# Qorvo_SVD register map
Vendor: Qorvo Inc; Series: ARMCM4; File version: 1.0
Registers are 8-bit, read-write, reset 0x0 unless marked. A register's access mark holds for its fields unless they carry their own. Offsets are from the block's base; [hi:lo] are bit positions.

## ADCIF
Base 0x40001040
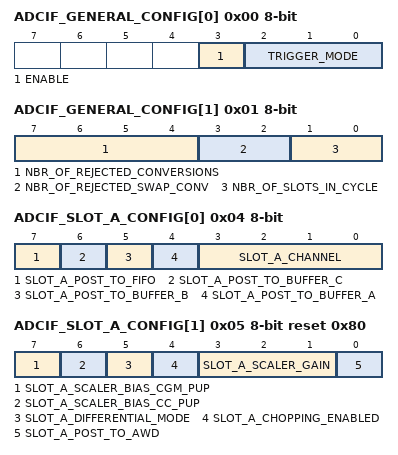
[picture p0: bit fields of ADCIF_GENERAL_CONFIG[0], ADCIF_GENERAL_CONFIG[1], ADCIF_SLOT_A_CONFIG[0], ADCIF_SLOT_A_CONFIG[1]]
0x00 ADCIF_GENERAL_CONFIG[0]
  [3] ENABLE — Enables the adc to perform measurements
  [2:0] TRIGGER_MODE — Defines when the adc measurement is triggered - see enum for possibilities
0x01 ADCIF_GENERAL_CONFIG[1]
  [7:4] NBR_OF_REJECTED_CONVERSIONS — Sets the number of conversions that are rejected between 2 measurements on different channels - acoounts for channel select mux settling time
  [3:2] NBR_OF_REJECTED_SWAP_CONV — Sets the number of conversions that are rejected in a chopped measurement after changing the adc swap input
  [1:0] NBR_OF_SLOTS_IN_CYCLE — Sets the number of slots that are used in a measurement cycle. Up to 4 slots can be used, resulting in an way to measure 4 different channels per cycle. This setting specifies the number of slots-1 (so setting 0 -> 1 slot, setting 3 -> 4 slots)
0x02 ADCIF_GENERAL_CONFIG[2]
  [0] USE_FRACT_CLOCK_AS_SAMPLE_CLK_SOURCE — When set to 1, the clock that is sent to the analog domain is coming from the fractional clock generator (needs bbpll to be on). If not set the clock is a 4MHz 50pct duty cycle clock
0x04 ADCIF_SLOT_A_CONFIG[0]
  [7] SLOT_A_POST_TO_FIFO — post result to result fifo
  [6] SLOT_A_POST_TO_BUFFER_C — post result to third result buffer
  [5] SLOT_A_POST_TO_BUFFER_B — post result to second result buffer
  [4] SLOT_A_POST_TO_BUFFER_A — post result to first result buffer
  [3:0] SLOT_A_CHANNEL — The adc channel for slot a
0x05 ADCIF_SLOT_A_CONFIG[1] reset 0x80
  [7] SLOT_A_SCALER_BIAS_CGM_PUP — constant gm pup
  [6] SLOT_A_SCALER_BIAS_CC_PUP — constant current pup
  [5] SLOT_A_DIFFERENTIAL_MODE — idicates whether we want to do a single_ended or differential measurement
  [4] SLOT_A_CHOPPING_ENABLED — idicates whether we want to do a chopped measurement to cancel out offset errors in the signal path
  [3:1] SLOT_A_SCALER_GAIN — gain to use on the input, note that this is differential gain. Single ended to differential gain will be half of this.
  [0] SLOT_A_POST_TO_AWD — post result to analog watchdog
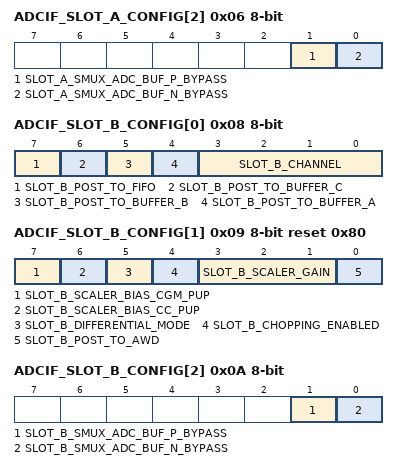
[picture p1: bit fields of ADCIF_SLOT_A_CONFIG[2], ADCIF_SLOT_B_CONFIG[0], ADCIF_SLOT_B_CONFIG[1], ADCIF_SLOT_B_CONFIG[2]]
0x06 ADCIF_SLOT_A_CONFIG[2]
  [1] SLOT_A_SMUX_ADC_BUF_P_BYPASS — bypasses the unity gain buffer (buffer will be forced off) for p-input adc
  [0] SLOT_A_SMUX_ADC_BUF_N_BYPASS — bypasses the unity gain buffer (buffer will be forced off) for n-input adc
0x08 ADCIF_SLOT_B_CONFIG[0]
  [7] SLOT_B_POST_TO_FIFO — post result to result fifo
  [6] SLOT_B_POST_TO_BUFFER_C — post result to third result buffer
  [5] SLOT_B_POST_TO_BUFFER_B — post result to second result buffer
  [4] SLOT_B_POST_TO_BUFFER_A — post result to first result buffer
  [3:0] SLOT_B_CHANNEL — The adc channel for slot b
0x09 ADCIF_SLOT_B_CONFIG[1] reset 0x80
  [7] SLOT_B_SCALER_BIAS_CGM_PUP — constant gm pup
  [6] SLOT_B_SCALER_BIAS_CC_PUP — constant current pup
  [5] SLOT_B_DIFFERENTIAL_MODE — idicates whether we want to do a single_ended or differential measurement
  [4] SLOT_B_CHOPPING_ENABLED — idicates whether we want to do a chopped measurement to cancel out offset errors in the signal path
  [3:1] SLOT_B_SCALER_GAIN — gain to use on the input, note that this is differential gain. Single ended to differential gain will be half of this.
  [0] SLOT_B_POST_TO_AWD — post result to analog watchdog
0x0A ADCIF_SLOT_B_CONFIG[2]
  [1] SLOT_B_SMUX_ADC_BUF_P_BYPASS — bypasses the unity gain buffer (buffer will be forced off) for p-input adc
  [0] SLOT_B_SMUX_ADC_BUF_N_BYPASS — bypasses the unity gain buffer (buffer will be forced off) for n-input adc
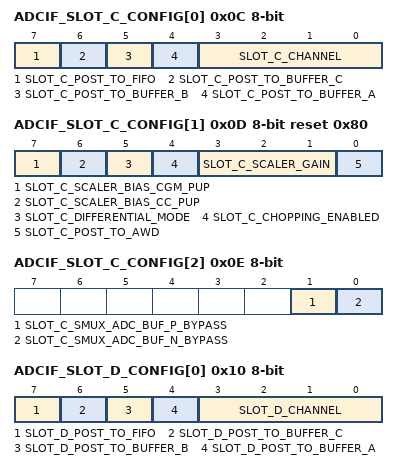
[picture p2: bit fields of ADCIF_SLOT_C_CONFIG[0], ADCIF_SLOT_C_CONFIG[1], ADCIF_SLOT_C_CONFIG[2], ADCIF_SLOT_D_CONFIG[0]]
0x0C ADCIF_SLOT_C_CONFIG[0]
  [7] SLOT_C_POST_TO_FIFO — post result to result fifo
  [6] SLOT_C_POST_TO_BUFFER_C — post result to third result buffer
  [5] SLOT_C_POST_TO_BUFFER_B — post result to second result buffer
  [4] SLOT_C_POST_TO_BUFFER_A — post result to first result buffer
  [3:0] SLOT_C_CHANNEL — The adc channel for slot c
0x0D ADCIF_SLOT_C_CONFIG[1] reset 0x80
  [7] SLOT_C_SCALER_BIAS_CGM_PUP — constant gm pup
  [6] SLOT_C_SCALER_BIAS_CC_PUP — constant current pup
  [5] SLOT_C_DIFFERENTIAL_MODE — idicates whether we want to do a single_ended or differential measurement
  [4] SLOT_C_CHOPPING_ENABLED — idicates whether we want to do a chopped measurement to cancel out offset errors in the signal path
  [3:1] SLOT_C_SCALER_GAIN — gain to use on the input, note that this is differential gain. Single ended to differential gain will be half of this.
  [0] SLOT_C_POST_TO_AWD — post result to analog watchdog
0x0E ADCIF_SLOT_C_CONFIG[2]
  [1] SLOT_C_SMUX_ADC_BUF_P_BYPASS — bypasses the unity gain buffer (buffer will be forced off) for p-input adc
  [0] SLOT_C_SMUX_ADC_BUF_N_BYPASS — bypasses the unity gain buffer (buffer will be forced off) for n-input adc
0x10 ADCIF_SLOT_D_CONFIG[0]
  [7] SLOT_D_POST_TO_FIFO — post result to result fifo
  [6] SLOT_D_POST_TO_BUFFER_C — post result to third result buffer
  [5] SLOT_D_POST_TO_BUFFER_B — post result to second result buffer
  [4] SLOT_D_POST_TO_BUFFER_A — post result to first result buffer
  [3:0] SLOT_D_CHANNEL — The adc channel for slot d
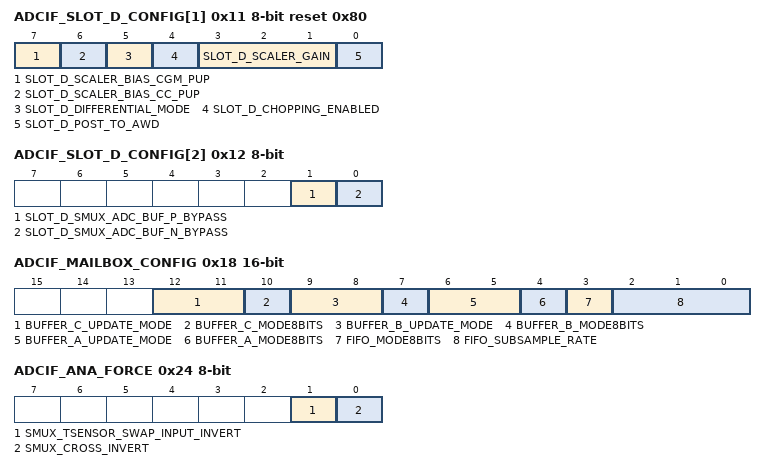
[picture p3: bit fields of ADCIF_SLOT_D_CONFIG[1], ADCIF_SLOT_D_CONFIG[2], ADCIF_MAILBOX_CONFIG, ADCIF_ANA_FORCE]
0x11 ADCIF_SLOT_D_CONFIG[1] reset 0x80
  [7] SLOT_D_SCALER_BIAS_CGM_PUP — constant gm pup
  [6] SLOT_D_SCALER_BIAS_CC_PUP — constant current pup
  [5] SLOT_D_DIFFERENTIAL_MODE — idicates whether we want to do a single_ended or differential measurement
  [4] SLOT_D_CHOPPING_ENABLED — idicates whether we want to do a chopped measurement to cancel out offset errors in the signal path
  [3:1] SLOT_D_SCALER_GAIN — gain to use on the input, note that this is differential gain. Single ended to differential gain will be half of this.
  [0] SLOT_D_POST_TO_AWD — post result to analog watchdog
0x12 ADCIF_SLOT_D_CONFIG[2]
  [1] SLOT_D_SMUX_ADC_BUF_P_BYPASS — bypasses the unity gain buffer (buffer will be forced off) for p-input adc
  [0] SLOT_D_SMUX_ADC_BUF_N_BYPASS — bypasses the unity gain buffer (buffer will be forced off) for n-input adc
0x14 ADCIF_PRESET_MAX_VALUE 16-bit
  [9:0] PRESET_MAX_VALUE — This is the value that is used to preset the awd/buffer_a/b/c maximal value when buffer_a_preset / buffer_b_preset / buffer_c_preset / awd_preset is applied
0x16 ADCIF_PRESET_MIN_VALUE 16-bit
  [9:0] PRESET_MIN_VALUE — This is the value that is used to preset the awd/buffer_a/b/c minimal value when buffer_a_preset / buffer_b_preset / buffer_c_preset / awd_preset is applied
0x18 ADCIF_MAILBOX_CONFIG 16-bit
  [12:11] BUFFER_C_UPDATE_MODE — Sets the update mode of buffer c (normal, minimum hold, maximum hold or out-of-range mode)
  [10] BUFFER_C_MODE8BITS — Puts buffer c in 8 bits mode (iso 10 bits mode) - the result is in the LSB bits of buffer_c
  [9:8] BUFFER_B_UPDATE_MODE — Sets the update mode of buffer b (normal, minimum hold, maximum hold or out-of-range mode)
  [7] BUFFER_B_MODE8BITS — Puts buffer b in 8 bits mode (iso 10 bits mode) - the result is in the LSB bits of buffer_b
  [6:5] BUFFER_A_UPDATE_MODE — Sets the update mode of buffer a (normal, minimum hold, maximum hold or out-of-range mode)
  [4] BUFFER_A_MODE8BITS — Puts buffer a in 8 bits mode (iso 10 bits mode) - the result is in the LSB bits of buffer_a
  [3] FIFO_MODE8BITS — Puts fifo in 8 bits mode (iso 10 bits mode) - the result is in the LSB bits of fifo
  [2:0] FIFO_SUBSAMPLE_RATE — Defines the rate at which samples are put into the fifo (every fifo_subsample_rate+1 'th sample is used)
0x1E ADCIF_BUFFER_A_RESULT_PB 16-bit ro
  [7:0] BUFFER_A_RESULT_0 — LSB bits of the result buffer a
  [9:0] BUFFER_A_RESULT — result buffer a
0x20 ADCIF_BUFFER_B_RESULT_PB 16-bit ro
  [7:0] BUFFER_B_RESULT_0 — LSB bits of the result buffer b
  [9:0] BUFFER_B_RESULT — result buffer b
0x22 ADCIF_BUFFER_C_RESULT_PB 16-bit ro
  [7:0] BUFFER_C_RESULT_0 — LSB bits of the result buffer c
  [9:0] BUFFER_C_RESULT — result buffer c
0x24 ADCIF_ANA_FORCE
  [1] SMUX_TSENSOR_SWAP_INPUT_INVERT — makes it able to invert the generated swap signal.
  [0] SMUX_CROSS_INVERT — makes it able to invert the generated swap signal.
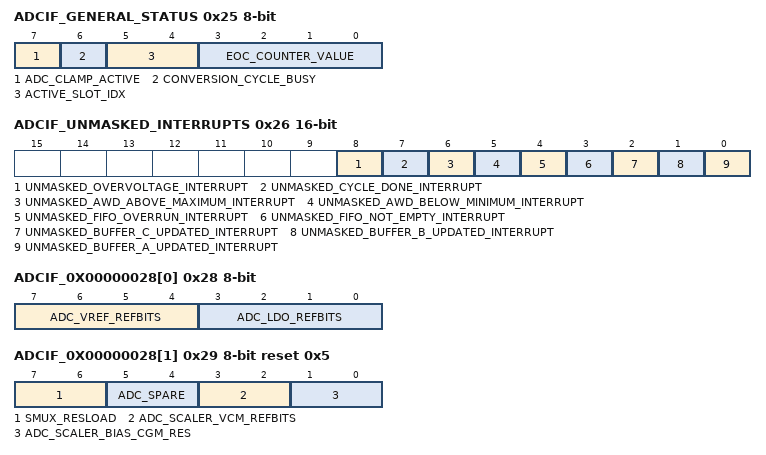
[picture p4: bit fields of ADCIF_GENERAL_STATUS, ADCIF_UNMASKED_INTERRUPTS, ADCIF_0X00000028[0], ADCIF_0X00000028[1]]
0x25 ADCIF_GENERAL_STATUS ro
  [7] ADC_CLAMP_ACTIVE — Flag indicating that the voltage at the ADC input is too high
  [6] CONVERSION_CYCLE_BUSY — Indicates that a conversion is ongoing
  [5:4] ACTIVE_SLOT_IDX — The slot index of the currently active slot
  [3:0] EOC_COUNTER_VALUE — The current value of the end of conversion counter
0x26 ADCIF_UNMASKED_INTERRUPTS 16-bit ro
  [8] UNMASKED_OVERVOLTAGE_INTERRUPT — interrupt indicating that the voltage at the ADC input was too high during a measurement
  [7] UNMASKED_CYCLE_DONE_INTERRUPT — Interrupts generated when a complete measurement cycle finished
  [6] UNMASKED_AWD_ABOVE_MAXIMUM_INTERRUPT — Interrupt triggered when the value is above the configured maximum
  [5] UNMASKED_AWD_BELOW_MINIMUM_INTERRUPT — Interrupt triggered when the value is below the configured minimum
  [4] UNMASKED_FIFO_OVERRUN_INTERRUPT — Interrupts generated when new data was available while FIFO was full
  [3] UNMASKED_FIFO_NOT_EMPTY_INTERRUPT — Interrupts generated when there is data in the FIFO
  [2] UNMASKED_BUFFER_C_UPDATED_INTERRUPT — Interrupt triggered when the value in buffer c updated
  [1] UNMASKED_BUFFER_B_UPDATED_INTERRUPT — Interrupt triggered when the value in buffer b updated
  [0] UNMASKED_BUFFER_A_UPDATED_INTERRUPT — Interrupt triggered when the value in buffer a updated
0x28 ADCIF_0X00000028[0]
  [7:4] ADC_VREF_REFBITS — tuning bits for the adc reference ldo output voltage
  [3:0] ADC_LDO_REFBITS — tuning bits for the gp-adc analogue ldo output voltage
0x29 ADCIF_0X00000028[1] reset 0x5
  [7:6] SMUX_RESLOAD — 2 bits resistive load on testbus:0=900k, 1=300k, 2=100k, 3=33k
  [5:4] ADC_SPARE — spare
  [3:2] ADC_SCALER_VCM_REFBITS
  [1:0] ADC_SCALER_BIAS_CGM_RES — set resistor ladder for bias current of constant-gm block
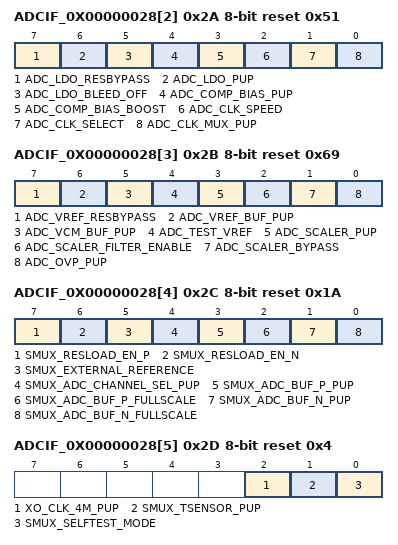
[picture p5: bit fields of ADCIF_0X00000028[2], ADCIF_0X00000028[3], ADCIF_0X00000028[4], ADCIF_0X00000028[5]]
0x2A ADCIF_0X00000028[2] reset 0x51
  [7] ADC_LDO_RESBYPASS — signal to bypass the lpf resistor in the gp-adc analogue ldo
  [6] ADC_LDO_PUP — pup signal for the gp-adc analogue ldo
  [5] ADC_LDO_BLEED_OFF — disable for the bleed transistor at the gp-adc analogue ldo output
  [4] ADC_COMP_BIAS_PUP
  [3] ADC_COMP_BIAS_BOOST — doubles the bias current in the comparator
  [2] ADC_CLK_SPEED
  [1] ADC_CLK_SELECT
  [0] ADC_CLK_MUX_PUP
0x2B ADCIF_0X00000028[3] reset 0x69
  [7] ADC_VREF_RESBYPASS — signal to bypass the lpf resistor in the adc reference ldo
  [6] ADC_VREF_BUF_PUP — enable signal for the adc vddref buffer
  [5] ADC_VCM_BUF_PUP — enable signal for the adc vcm buffer, 1.2v
  [4] ADC_TEST_VREF — connect reference voltage directly to adc for measuring gain error
  [3] ADC_SCALER_PUP
  [2] ADC_SCALER_FILTER_ENABLE
  [1] ADC_SCALER_BYPASS
  [0] ADC_OVP_PUP — enables overvoltage detection (previously smux)
0x2C ADCIF_0X00000028[4] reset 0x1A
  [7] SMUX_RESLOAD_EN_P — enable resistive load on p-side of testbus
  [6] SMUX_RESLOAD_EN_N — enable resistive load on n-side of testbus
  [5] SMUX_EXTERNAL_REFERENCE — use
  [4] SMUX_ADC_CHANNEL_SEL_PUP — enabled any anio to be connected to adc-bus
  [3] SMUX_ADC_BUF_P_PUP — enables unity-gain buffer from bus to adc for p-input adc
  [2] SMUX_ADC_BUF_P_FULLSCALE — switches unity gain buffer to use full scale (enabling nmos input pair as well) for p-input adc
  [1] SMUX_ADC_BUF_N_PUP — enables unity-gain buffer from bus to adc for n-input adc
  [0] SMUX_ADC_BUF_N_FULLSCALE — switches unity gain buffer to use full scale (enabling nmos input pair as well) for n-input adc
0x2D ADCIF_0X00000028[5] reset 0x4
  [2] XO_CLK_4M_PUP — enables the 4 mhz clock to the general purpose adc block
  [1] SMUX_TSENSOR_PUP — enables temperature sensor
  [0] SMUX_SELFTEST_MODE — selects either offset or gain mode for internal self test
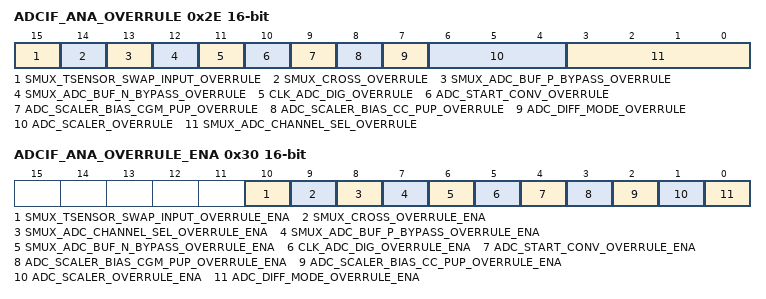
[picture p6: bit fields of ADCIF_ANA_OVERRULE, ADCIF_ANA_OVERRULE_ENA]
0x2E ADCIF_ANA_OVERRULE 16-bit
  [15] SMUX_TSENSOR_SWAP_INPUT_OVERRULE — swaps differential outputs of temperature sensor that go to gp-adc
  [14] SMUX_CROSS_OVERRULE — swaps anio connection from p/n to n/p on bus for adc, (differential input of adc). this applies to the inputs: anio[0], anio[1], testbus_ch0, testbus_ch1, testbus_ch2, and vbat.
  [13] SMUX_ADC_BUF_P_BYPASS_OVERRULE — bypasses the unity gain buffer (buffer will be forced off) for p-input adc
  [12] SMUX_ADC_BUF_N_BYPASS_OVERRULE — bypasses the unity gain buffer (buffer will be forced off) for n-input adc
  [11] CLK_ADC_DIG_OVERRULE — adc conversion clock connected to synthesizer
  [10] ADC_START_CONV_OVERRULE — request to do a conversion, 1.2v
  [9] ADC_SCALER_BIAS_CGM_PUP_OVERRULE
  [8] ADC_SCALER_BIAS_CC_PUP_OVERRULE
  [7] ADC_DIFF_MODE_OVERRULE — selects differential mode usage =1, otherwise single ended adc input
  [6:4] ADC_SCALER_OVERRULE
  [3:0] SMUX_ADC_CHANNEL_SEL_OVERRULE — selects which anio is connected to adc-bus
0x30 ADCIF_ANA_OVERRULE_ENA 16-bit
  [10] SMUX_TSENSOR_SWAP_INPUT_OVERRULE_ENA — swaps differential outputs of temperature sensor that go to gp-adc
  [9] SMUX_CROSS_OVERRULE_ENA — swaps anio connection from p/n to n/p on bus for adc, (differential input of adc). this applies to the inputs: anio[0], anio[1], testbus_ch0, testbus_ch1, testbus_ch2, and vbat.
  [8] SMUX_ADC_CHANNEL_SEL_OVERRULE_ENA — selects which anio is connected to adc-bus
  [7] SMUX_ADC_BUF_P_BYPASS_OVERRULE_ENA — bypasses the unity gain buffer (buffer will be forced off) for p-input adc
  [6] SMUX_ADC_BUF_N_BYPASS_OVERRULE_ENA — bypasses the unity gain buffer (buffer will be forced off) for n-input adc
  [5] CLK_ADC_DIG_OVERRULE_ENA — adc conversion clock connected to synthesizer
  [4] ADC_START_CONV_OVERRULE_ENA — request to do a conversion, 1.2v
  [3] ADC_SCALER_BIAS_CGM_PUP_OVERRULE_ENA
  [2] ADC_SCALER_BIAS_CC_PUP_OVERRULE_ENA
  [1] ADC_SCALER_OVERRULE_ENA
  [0] ADC_DIFF_MODE_OVERRULE_ENA — selects differential mode usage =1, otherwise single ended adc input
